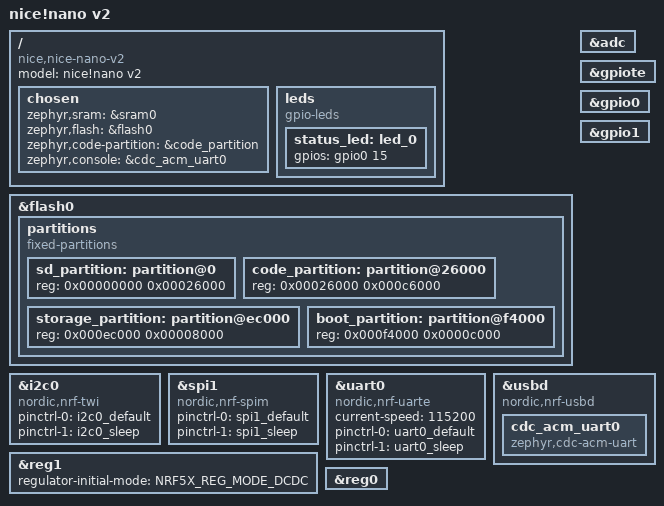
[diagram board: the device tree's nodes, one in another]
/dts-v1/;
#include <nordic/nrf52840_qiaa.dtsi>
#include "nice_nano_v2-pinctrl.dtsi"

/ {
	model = "nice!nano v2";
	compatible = "nice,nice-nano-v2";

	chosen {
		zephyr,sram = &sram0;
		zephyr,flash = &flash0;
		zephyr,code-partition = &code_partition;
		zephyr,console = &cdc_acm_uart0;
	};

	leds {
        compatible = "gpio-leds";
        status_led: led_0 {
            gpios = <&gpio0 15 GPIO_ACTIVE_HIGH>;
        };
    };
};

&flash0 {
    partitions {
        compatible = "fixed-partitions";
        #address-cells = <1>;
        #size-cells = <1>;

        sd_partition: partition@0 {
            reg = <0x00000000 0x00026000>;
        };

        code_partition: partition@26000 {
            reg = <0x00026000 0x000c6000>;
        };

        storage_partition: partition@ec000 {
            reg = <0x000ec000 0x00008000>;
        };

        boot_partition: partition@f4000 {
            reg = <0x000f4000 0x0000c000>;
        };
    };
};

&adc {
    status = "okay";
};

&gpiote {
    status = "okay";
};

&gpio0 {
    status = "okay";
};

&gpio1 {
    status = "okay";
};

&i2c0 {
    compatible = "nordic,nrf-twi";
    pinctrl-0 = <&i2c0_default>;
    pinctrl-1 = <&i2c0_sleep>;
    pinctrl-names = "default", "sleep";
};

&spi1 {
    compatible = "nordic,nrf-spim";
    pinctrl-0 = <&spi1_default>;
    pinctrl-1 = <&spi1_sleep>;
    pinctrl-names = "default", "sleep";
};

&uart0 {
    compatible = "nordic,nrf-uarte";
    current-speed = <115200>;
    pinctrl-0 = <&uart0_default>;
    pinctrl-1 = <&uart0_sleep>;
    pinctrl-names = "default", "sleep";
};

zephyr_udc0: &usbd {
	compatible = "nordic,nrf-usbd";
	status = "okay";
	cdc_acm_uart0: cdc_acm_uart0 {
		compatible = "zephyr,cdc-acm-uart";
	};
};

/* configure REG/REG1 in DC/DC mode */
&reg1 {
	regulator-initial-mode = <NRF5X_REG_MODE_DCDC>;
};

/* enable REG0 (HV mode) */
&reg0 {
    status = "okay";
};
